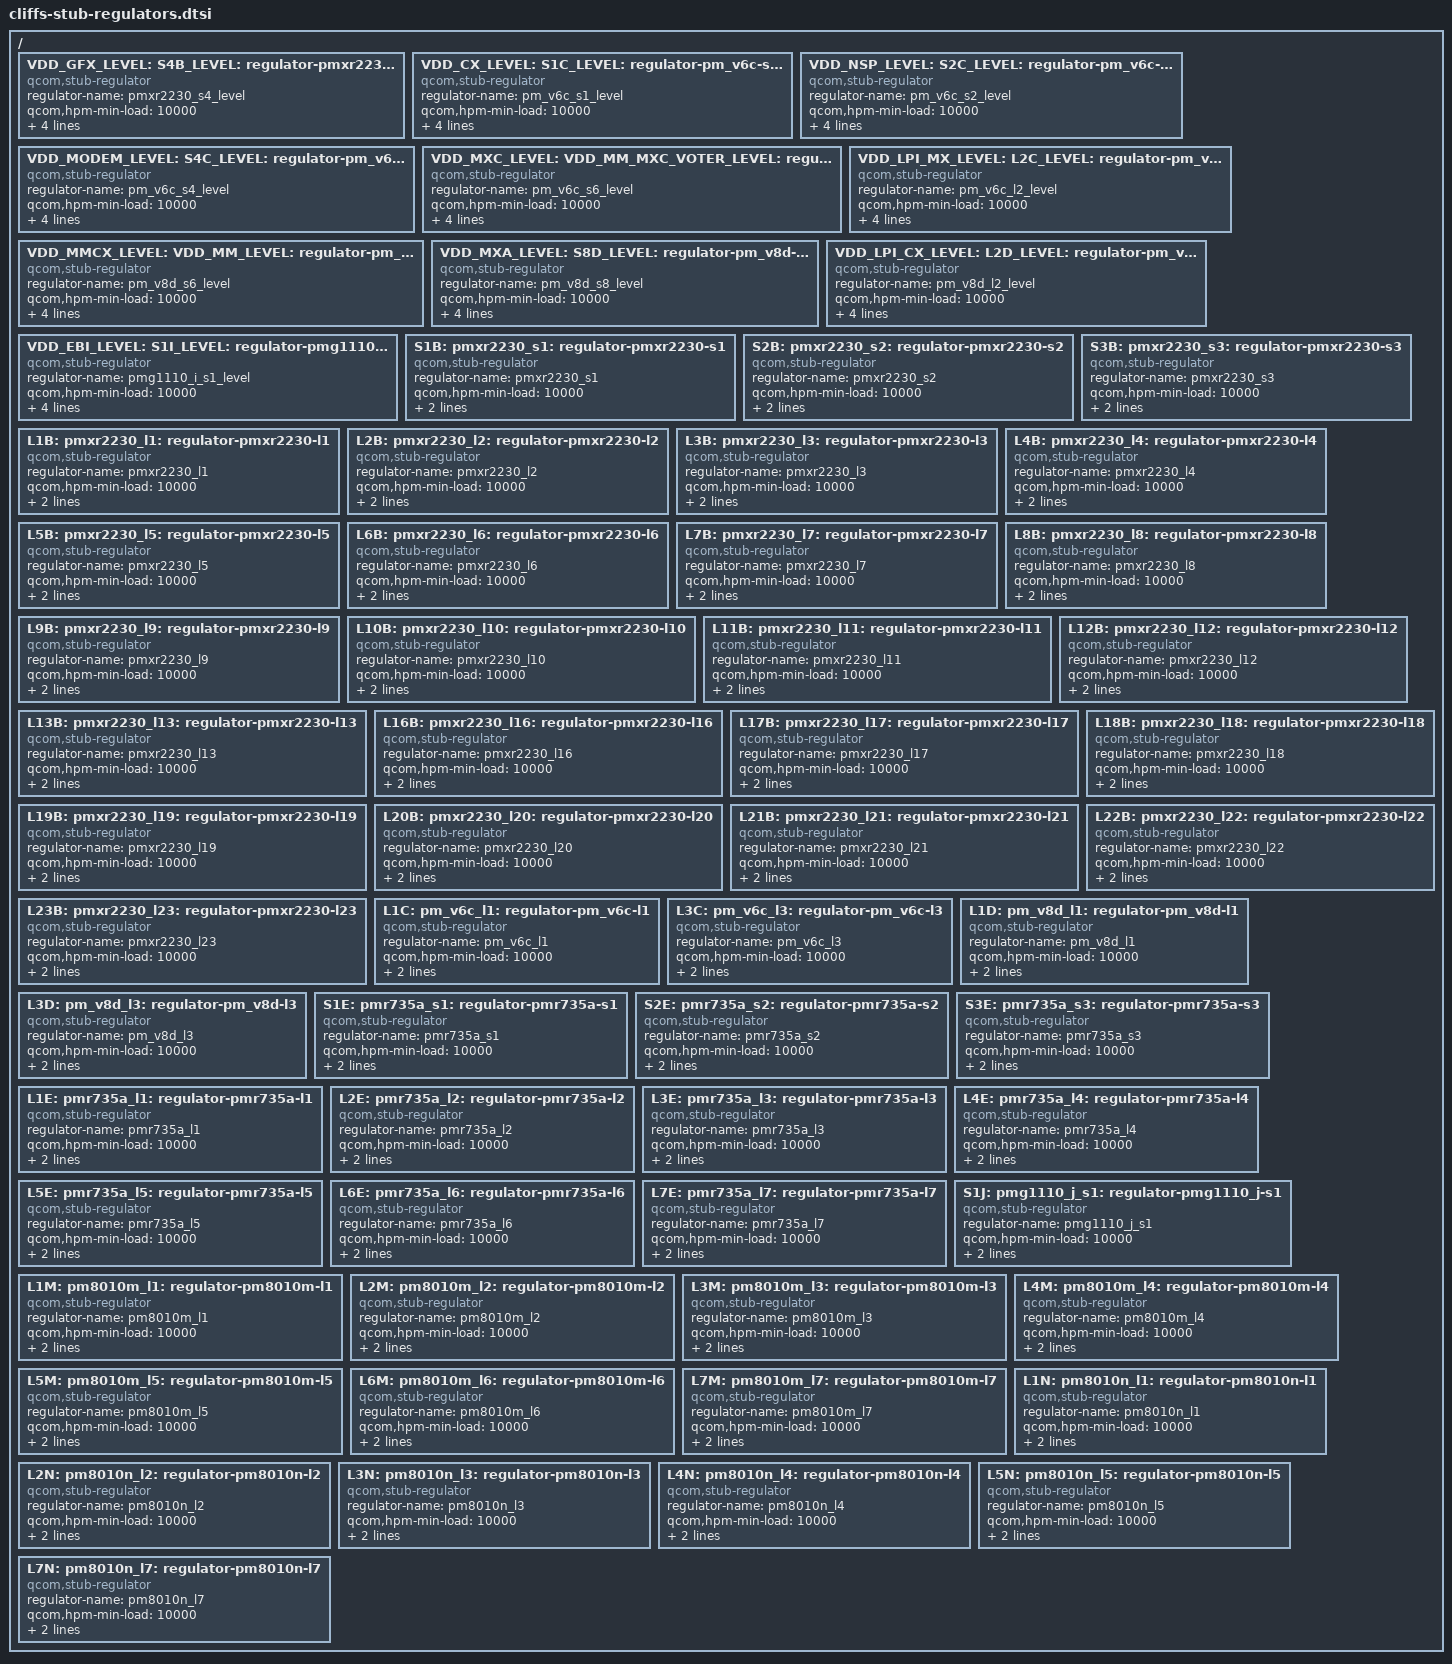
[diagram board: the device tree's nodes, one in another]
#include <dt-bindings/regulator/qcom,rpmh-regulator-levels.h>

/ {
	VDD_GFX_LEVEL:
	S4B_LEVEL:
	pmxr2230_s4_level: regulator-pmxr2230-s4-level {
		compatible = "qcom,stub-regulator";
		regulator-name = "pmxr2230_s4_level";
		qcom,hpm-min-load = <10000>;
		regulator-min-microvolt =
			<RPMH_REGULATOR_LEVEL_RETENTION>;
		regulator-max-microvolt = <RPMH_REGULATOR_LEVEL_MAX>;
	};

	VDD_CX_LEVEL:
	S1C_LEVEL:
	pm_v6c_s1_level: regulator-pm_v6c-s1-level {
		compatible = "qcom,stub-regulator";
		regulator-name = "pm_v6c_s1_level";
		qcom,hpm-min-load = <10000>;
		regulator-min-microvolt =
			<RPMH_REGULATOR_LEVEL_RETENTION>;
		regulator-max-microvolt = <RPMH_REGULATOR_LEVEL_MAX>;
	};

	VDD_NSP_LEVEL:
	S2C_LEVEL:
	pm_v6c_s2_level: regulator-pm_v6c-s2-level {
		compatible = "qcom,stub-regulator";
		regulator-name = "pm_v6c_s2_level";
		qcom,hpm-min-load = <10000>;
		regulator-min-microvolt =
			<RPMH_REGULATOR_LEVEL_RETENTION>;
		regulator-max-microvolt = <RPMH_REGULATOR_LEVEL_MAX>;
	};

	VDD_MODEM_LEVEL:
	S4C_LEVEL:
	pm_v6c_s4_level: regulator-pm_v6c-s4-level {
		compatible = "qcom,stub-regulator";
		regulator-name = "pm_v6c_s4_level";
		qcom,hpm-min-load = <10000>;
		regulator-min-microvolt =
			<RPMH_REGULATOR_LEVEL_RETENTION>;
		regulator-max-microvolt = <RPMH_REGULATOR_LEVEL_MAX>;
	};

	VDD_MXC_LEVEL:
	VDD_MM_MXC_VOTER_LEVEL:
	VDD_GFX_MXC_VOTER_LEVEL:
	S6C_LEVEL:
	pm_v6c_s6_level: regulator-pm_v6c-s6-level {
		compatible = "qcom,stub-regulator";
		regulator-name = "pm_v6c_s6_level";
		qcom,hpm-min-load = <10000>;
		regulator-min-microvolt =
			<RPMH_REGULATOR_LEVEL_RETENTION>;
		regulator-max-microvolt = <RPMH_REGULATOR_LEVEL_MAX>;
	};

	VDD_LPI_MX_LEVEL:
	L2C_LEVEL:
	pm_v6c_l2_level: regulator-pm_v6c-l2-level {
		compatible = "qcom,stub-regulator";
		regulator-name = "pm_v6c_l2_level";
		qcom,hpm-min-load = <10000>;
		regulator-min-microvolt =
			<RPMH_REGULATOR_LEVEL_RETENTION>;
		regulator-max-microvolt = <RPMH_REGULATOR_LEVEL_MAX>;
	};

	VDD_MMCX_LEVEL:
	VDD_MM_LEVEL:
	S6D_LEVEL:
	pm_v8d_s6_level: regulator-pm_v8d-s6-level {
		compatible = "qcom,stub-regulator";
		regulator-name = "pm_v8d_s6_level";
		qcom,hpm-min-load = <10000>;
		regulator-min-microvolt =
			<RPMH_REGULATOR_LEVEL_RETENTION>;
		regulator-max-microvolt = <RPMH_REGULATOR_LEVEL_MAX>;
	};

	VDD_MXA_LEVEL:
	S8D_LEVEL:
	pm_v8d_s8_level: regulator-pm_v8d-s8-level {
		compatible = "qcom,stub-regulator";
		regulator-name = "pm_v8d_s8_level";
		qcom,hpm-min-load = <10000>;
		regulator-min-microvolt =
			<RPMH_REGULATOR_LEVEL_RETENTION>;
		regulator-max-microvolt = <RPMH_REGULATOR_LEVEL_MAX>;
	};

	VDD_LPI_CX_LEVEL:
	L2D_LEVEL:
	pm_v8d_l2_level: regulator-pm_v8d-l2-level {
		compatible = "qcom,stub-regulator";
		regulator-name = "pm_v8d_l2_level";
		qcom,hpm-min-load = <10000>;
		regulator-min-microvolt =
			<RPMH_REGULATOR_LEVEL_RETENTION>;
		regulator-max-microvolt = <RPMH_REGULATOR_LEVEL_MAX>;
	};

	VDD_EBI_LEVEL:
	S1I_LEVEL:
	pmg1110_i_s1_level: regulator-pmg1110_i-s1-level {
		compatible = "qcom,stub-regulator";
		regulator-name = "pmg1110_i_s1_level";
		qcom,hpm-min-load = <10000>;
		regulator-min-microvolt =
			<RPMH_REGULATOR_LEVEL_RETENTION>;
		regulator-max-microvolt = <RPMH_REGULATOR_LEVEL_MAX>;
	};

	S1B:
	pmxr2230_s1: regulator-pmxr2230-s1 {
		compatible = "qcom,stub-regulator";
		regulator-name = "pmxr2230_s1";
		qcom,hpm-min-load = <10000>;
		regulator-min-microvolt = <1856000>;
		regulator-max-microvolt = <2040000>;
	};

	S2B:
	pmxr2230_s2: regulator-pmxr2230-s2 {
		compatible = "qcom,stub-regulator";
		regulator-name = "pmxr2230_s2";
		qcom,hpm-min-load = <10000>;
		regulator-min-microvolt = <1020000>;
		regulator-max-microvolt = <2050000>;
	};

	S3B:
	pmxr2230_s3: regulator-pmxr2230-s3 {
		compatible = "qcom,stub-regulator";
		regulator-name = "pmxr2230_s3";
		qcom,hpm-min-load = <10000>;
		regulator-min-microvolt = <626000>;
		regulator-max-microvolt = <1040000>;
	};

	L1B:
	pmxr2230_l1: regulator-pmxr2230-l1 {
		compatible = "qcom,stub-regulator";
		regulator-name = "pmxr2230_l1";
		qcom,hpm-min-load = <10000>;
		regulator-min-microvolt = <866000>;
		regulator-max-microvolt = <958000>;
	};

	L2B:
	pmxr2230_l2: regulator-pmxr2230-l2 {
		compatible = "qcom,stub-regulator";
		regulator-name = "pmxr2230_l2";
		qcom,hpm-min-load = <10000>;
		regulator-min-microvolt = <720000>;
		regulator-max-microvolt = <950000>;
	};

	L3B:
	pmxr2230_l3: regulator-pmxr2230-l3 {
		compatible = "qcom,stub-regulator";
		regulator-name = "pmxr2230_l3";
		qcom,hpm-min-load = <10000>;
		regulator-min-microvolt = <830000>;
		regulator-max-microvolt = <920000>;
	};

	L4B:
	pmxr2230_l4: regulator-pmxr2230-l4 {
		compatible = "qcom,stub-regulator";
		regulator-name = "pmxr2230_l4";
		qcom,hpm-min-load = <10000>;
		regulator-min-microvolt = <1080000>;
		regulator-max-microvolt = <1320000>;
	};

	L5B:
	pmxr2230_l5: regulator-pmxr2230-l5 {
		compatible = "qcom,stub-regulator";
		regulator-name = "pmxr2230_l5";
		qcom,hpm-min-load = <10000>;
		regulator-min-microvolt = <1000000>;
		regulator-max-microvolt = <1980000>;
	};

	L6B:
	pmxr2230_l6: regulator-pmxr2230-l6 {
		compatible = "qcom,stub-regulator";
		regulator-name = "pmxr2230_l6";
		qcom,hpm-min-load = <10000>;
		regulator-min-microvolt = <1170000>;
		regulator-max-microvolt = <1370000>;
	};

	L7B:
	pmxr2230_l7: regulator-pmxr2230-l7 {
		compatible = "qcom,stub-regulator";
		regulator-name = "pmxr2230_l7";
		qcom,hpm-min-load = <10000>;
		regulator-min-microvolt = <1080000>;
		regulator-max-microvolt = <2000000>;
	};

	L8B:
	pmxr2230_l8: regulator-pmxr2230-l8 {
		compatible = "qcom,stub-regulator";
		regulator-name = "pmxr2230_l8";
		qcom,hpm-min-load = <10000>;
		regulator-min-microvolt = <1700000>;
		regulator-max-microvolt = <1900000>;
	};

	L9B:
	pmxr2230_l9: regulator-pmxr2230-l9 {
		compatible = "qcom,stub-regulator";
		regulator-name = "pmxr2230_l9";
		qcom,hpm-min-load = <10000>;
		regulator-min-microvolt = <756000>;
		regulator-max-microvolt = <816000>;
	};

	L10B:
	pmxr2230_l10: regulator-pmxr2230-l10 {
		compatible = "qcom,stub-regulator";
		regulator-name = "pmxr2230_l10";
		qcom,hpm-min-load = <10000>;
		regulator-min-microvolt = <866000>;
		regulator-max-microvolt = <931000>;
	};

	L11B:
	pmxr2230_l11: regulator-pmxr2230-l11 {
		compatible = "qcom,stub-regulator";
		regulator-name = "pmxr2230_l11";
		qcom,hpm-min-load = <10000>;
		regulator-min-microvolt = <1650000>;
		regulator-max-microvolt = <2000000>;
	};

	L12B:
	pmxr2230_l12: regulator-pmxr2230-l12 {
		compatible = "qcom,stub-regulator";
		regulator-name = "pmxr2230_l12";
		qcom,hpm-min-load = <10000>;
		regulator-min-microvolt = <2400000>;
		regulator-max-microvolt = <3300000>;
	};

	L13B:
	pmxr2230_l13: regulator-pmxr2230-l13 {
		compatible = "qcom,stub-regulator";
		regulator-name = "pmxr2230_l13";
		qcom,hpm-min-load = <10000>;
		regulator-min-microvolt = <2700000>;
		regulator-max-microvolt = <3300000>;
	};

	L16B:
	pmxr2230_l16: regulator-pmxr2230-l16 {
		compatible = "qcom,stub-regulator";
		regulator-name = "pmxr2230_l16";
		qcom,hpm-min-load = <10000>;
		regulator-min-microvolt = <2900000>;
		regulator-max-microvolt = <3544000>;
	};

	L17B:
	pmxr2230_l17: regulator-pmxr2230-l17 {
		compatible = "qcom,stub-regulator";
		regulator-name = "pmxr2230_l17";
		qcom,hpm-min-load = <10000>;
		regulator-min-microvolt = <2700000>;
		regulator-max-microvolt = <3300000>;
	};

	L18B:
	pmxr2230_l18: regulator-pmxr2230-l18 {
		compatible = "qcom,stub-regulator";
		regulator-name = "pmxr2230_l18";
		qcom,hpm-min-load = <10000>;
		regulator-min-microvolt = <1600000>;
		regulator-max-microvolt = <3544000>;
	};

	L19B:
	pmxr2230_l19: regulator-pmxr2230-l19 {
		compatible = "qcom,stub-regulator";
		regulator-name = "pmxr2230_l19";
		qcom,hpm-min-load = <10000>;
		regulator-min-microvolt = <2600000>;
		regulator-max-microvolt = <3544000>;
	};

	L20B:
	pmxr2230_l20: regulator-pmxr2230-l20 {
		compatible = "qcom,stub-regulator";
		regulator-name = "pmxr2230_l20";
		qcom,hpm-min-load = <10000>;
		regulator-min-microvolt = <1620000>;
		regulator-max-microvolt = <3544000>;
	};

	L21B:
	pmxr2230_l21: regulator-pmxr2230-l21 {
		compatible = "qcom,stub-regulator";
		regulator-name = "pmxr2230_l21";
		qcom,hpm-min-load = <10000>;
		regulator-min-microvolt = <1620000>;
		regulator-max-microvolt = <3544000>;
	};

	L22B:
	pmxr2230_l22: regulator-pmxr2230-l22 {
		compatible = "qcom,stub-regulator";
		regulator-name = "pmxr2230_l22";
		qcom,hpm-min-load = <10000>;
		regulator-min-microvolt = <2700000>;
		regulator-max-microvolt = <3400000>;
	};

	L23B:
	pmxr2230_l23: regulator-pmxr2230-l23 {
		compatible = "qcom,stub-regulator";
		regulator-name = "pmxr2230_l23";
		qcom,hpm-min-load = <10000>;
		regulator-min-microvolt = <1650000>;
		regulator-max-microvolt = <3544000>;
	};

	L1C:
	pm_v6c_l1: regulator-pm_v6c-l1 {
		compatible = "qcom,stub-regulator";
		regulator-name = "pm_v6c_l1";
		qcom,hpm-min-load = <10000>;
		regulator-min-microvolt = <870000>;
		regulator-max-microvolt = <970000>;
	};

	L3C:
	pm_v6c_l3: regulator-pm_v6c-l3 {
		compatible = "qcom,stub-regulator";
		regulator-name = "pm_v6c_l3";
		qcom,hpm-min-load = <10000>;
		regulator-min-microvolt = <320000>;
		regulator-max-microvolt = <2000000>;
	};

	L1D:
	pm_v8d_l1: regulator-pm_v8d-l1 {
		compatible = "qcom,stub-regulator";
		regulator-name = "pm_v8d_l1";
		qcom,hpm-min-load = <10000>;
		regulator-min-microvolt = <866000>;
		regulator-max-microvolt = <958000>;
	};

	L3D:
	pm_v8d_l3: regulator-pm_v8d-l3 {
		compatible = "qcom,stub-regulator";
		regulator-name = "pm_v8d_l3";
		qcom,hpm-min-load = <10000>;
		regulator-min-microvolt = <1140000>;
		regulator-max-microvolt = <1260000>;
	};

	S1E:
	pmr735a_s1: regulator-pmr735a-s1 {
		compatible = "qcom,stub-regulator";
		regulator-name = "pmr735a_s1";
		qcom,hpm-min-load = <10000>;
		regulator-min-microvolt = <1010000>;
		regulator-max-microvolt = <1170000>;
	};

	S2E:
	pmr735a_s2: regulator-pmr735a-s2 {
		compatible = "qcom,stub-regulator";
		regulator-name = "pmr735a_s2";
		qcom,hpm-min-load = <10000>;
		regulator-min-microvolt = <320000>;
		regulator-max-microvolt = <570000>;
	};

	S3E:
	pmr735a_s3: regulator-pmr735a-s3 {
		compatible = "qcom,stub-regulator";
		regulator-name = "pmr735a_s3";
		qcom,hpm-min-load = <10000>;
		regulator-min-microvolt = <2156000>;
		regulator-max-microvolt = <2400000>;
	};

	L1E:
	pmr735a_l1: regulator-pmr735a-l1 {
		compatible = "qcom,stub-regulator";
		regulator-name = "pmr735a_l1";
		qcom,hpm-min-load = <10000>;
		regulator-min-microvolt = <806000>;
		regulator-max-microvolt = <901000>;
	};

	L2E:
	pmr735a_l2: regulator-pmr735a-l2 {
		compatible = "qcom,stub-regulator";
		regulator-name = "pmr735a_l2";
		qcom,hpm-min-load = <10000>;
		regulator-min-microvolt = <920000>;
		regulator-max-microvolt = <969000>;
	};

	L3E:
	pmr735a_l3: regulator-pmr735a-l3 {
		compatible = "qcom,stub-regulator";
		regulator-name = "pmr735a_l3";
		qcom,hpm-min-load = <10000>;
		regulator-min-microvolt = <556000>;
		regulator-max-microvolt = <816000>;
	};

	L4E:
	pmr735a_l4: regulator-pmr735a-l4 {
		compatible = "qcom,stub-regulator";
		regulator-name = "pmr735a_l4";
		qcom,hpm-min-load = <10000>;
		regulator-min-microvolt = <1620000>;
		regulator-max-microvolt = <2000000>;
	};

	L5E:
	pmr735a_l5: regulator-pmr735a-l5 {
		compatible = "qcom,stub-regulator";
		regulator-name = "pmr735a_l5";
		qcom,hpm-min-load = <10000>;
		regulator-min-microvolt = <1100000>;
		regulator-max-microvolt = <1304000>;
	};

	L6E:
	pmr735a_l6: regulator-pmr735a-l6 {
		compatible = "qcom,stub-regulator";
		regulator-name = "pmr735a_l6";
		qcom,hpm-min-load = <10000>;
		regulator-min-microvolt = <1080000>;
		regulator-max-microvolt = <1304000>;
	};

	L7E:
	pmr735a_l7: regulator-pmr735a-l7 {
		compatible = "qcom,stub-regulator";
		regulator-name = "pmr735a_l7";
		qcom,hpm-min-load = <10000>;
		regulator-min-microvolt = <1620000>;
		regulator-max-microvolt = <3300000>;
	};

	S1J:
	pmg1110_j_s1: regulator-pmg1110_j-s1 {
		compatible = "qcom,stub-regulator";
		regulator-name = "pmg1110_j_s1";
		qcom,hpm-min-load = <10000>;
		regulator-min-microvolt = <320000>;
		regulator-max-microvolt = <1352000>;
	};

	L1M:
	pm8010m_l1: regulator-pm8010m-l1 {
		compatible = "qcom,stub-regulator";
		regulator-name = "pm8010m_l1";
		qcom,hpm-min-load = <10000>;
		regulator-min-microvolt = <1050000>;
		regulator-max-microvolt = <1180000>;
	};

	L2M:
	pm8010m_l2: regulator-pm8010m-l2 {
		compatible = "qcom,stub-regulator";
		regulator-name = "pm8010m_l2";
		qcom,hpm-min-load = <10000>;
		regulator-min-microvolt = <950000>;
		regulator-max-microvolt = <1150000>;
	};

	L3M:
	pm8010m_l3: regulator-pm8010m-l3 {
		compatible = "qcom,stub-regulator";
		regulator-name = "pm8010m_l3";
		qcom,hpm-min-load = <10000>;
		regulator-min-microvolt = <2700000>;
		regulator-max-microvolt = <2900000>;
	};

	L4M:
	pm8010m_l4: regulator-pm8010m-l4 {
		compatible = "qcom,stub-regulator";
		regulator-name = "pm8010m_l4";
		qcom,hpm-min-load = <10000>;
		regulator-min-microvolt = <2700000>;
		regulator-max-microvolt = <2900000>;
	};

	L5M:
	pm8010m_l5: regulator-pm8010m-l5 {
		compatible = "qcom,stub-regulator";
		regulator-name = "pm8010m_l5";
		qcom,hpm-min-load = <10000>;
		regulator-min-microvolt = <2700000>;
		regulator-max-microvolt = <2900000>;
	};

	L6M:
	pm8010m_l6: regulator-pm8010m-l6 {
		compatible = "qcom,stub-regulator";
		regulator-name = "pm8010m_l6";
		qcom,hpm-min-load = <10000>;
		regulator-min-microvolt = <2700000>;
		regulator-max-microvolt = <2900000>;
	};

	L7M:
	pm8010m_l7: regulator-pm8010m-l7 {
		compatible = "qcom,stub-regulator";
		regulator-name = "pm8010m_l7";
		qcom,hpm-min-load = <10000>;
		regulator-min-microvolt = <2700000>;
		regulator-max-microvolt = <3000000>;
	};

	L1N:
	pm8010n_l1: regulator-pm8010n-l1 {
		compatible = "qcom,stub-regulator";
		regulator-name = "pm8010n_l1";
		qcom,hpm-min-load = <10000>;
		regulator-min-microvolt = <1050000>;
		regulator-max-microvolt = <1200000>;
	};

	L2N:
	pm8010n_l2: regulator-pm8010n-l2 {
		compatible = "qcom,stub-regulator";
		regulator-name = "pm8010n_l2";
		qcom,hpm-min-load = <10000>;
		regulator-min-microvolt = <950000>;
		regulator-max-microvolt = <1150000>;
	};

	L3N:
	pm8010n_l3: regulator-pm8010n-l3 {
		compatible = "qcom,stub-regulator";
		regulator-name = "pm8010n_l3";
		qcom,hpm-min-load = <10000>;
		regulator-min-microvolt = <1792000>;
		regulator-max-microvolt = <1900000>;
	};

	L4N:
	pm8010n_l4: regulator-pm8010n-l4 {
		compatible = "qcom,stub-regulator";
		regulator-name = "pm8010n_l4";
		qcom,hpm-min-load = <10000>;
		regulator-min-microvolt = <1792000>;
		regulator-max-microvolt = <1900000>;
	};

	L5N:
	pm8010n_l5: regulator-pm8010n-l5 {
		compatible = "qcom,stub-regulator";
		regulator-name = "pm8010n_l5";
		qcom,hpm-min-load = <10000>;
		regulator-min-microvolt = <1504000>;
		regulator-max-microvolt = <1980000>;
	};

	L7N:
	pm8010n_l7: regulator-pm8010n-l7 {
		compatible = "qcom,stub-regulator";
		regulator-name = "pm8010n_l7";
		qcom,hpm-min-load = <10000>;
		regulator-min-microvolt = <3130000>;
		regulator-max-microvolt = <3470000>;
	};
};
